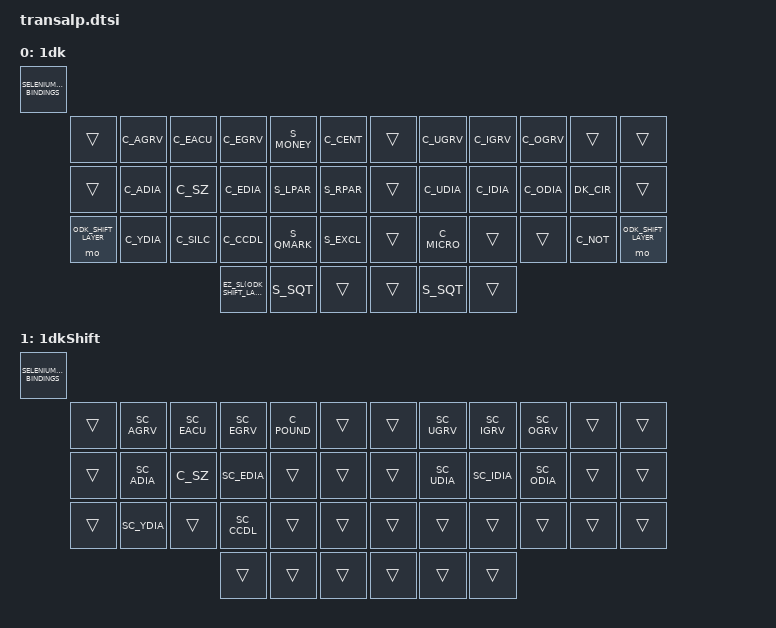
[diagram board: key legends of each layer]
#ifndef USE_ALPHA_ON_OUTER_KEYS

/**
 * This adds a dead key (1dk) to access all common German/French/Italian chars.
 * (Note that QWERTZ-ch natively supports these three languages.)
 *
 * Recommended layouts:
 *  - QWERTZ-ch, used in Switzerland, Luxembourg and Lichtenstein
 *  - QWERTZ-de, used in Germany and Austria
 *  - QWERTY-it, used in Italy (TODO)
 *
 * Language-specific chars:
 *  - German: äöü (diaeresis), ß
 *  - French: é (acute), èàù (grave), ç (cedilla), âêîôû (circumflex), ëïüÿ (diaeresis), œ, æ
 *  - Italian: é (acute), àèìòù (grave)
 *
 * Unsupported chars: (not supported by QWERTZ-de/AZERTY-fr/QWERTY-it, resp.)
 *  - German: uppercase ß
 *  - French: œ, æ
 *  - Italian: ő, circumflex (rare / deprecated)
 *  - advanced punctuation signs: „“, «», …, –—
 *
 * Some of this unsupported chars would be nice to have, and could be added
 * with CP1252 or other OS-specific input methods.
**/

#define ODK_LAYER        EXTRA_LAYERS_START_INDEX
#define ODK_SHIFT_LAYER (EXTRA_LAYERS_START_INDEX + 1)

#define  K_ODKS    &mo ODK_SHIFT_LAYER  // Shift key in the 1dk layer
#define SK_ODKS &EZ_SL(ODK_SHIFT_LAYER) // Shift key in the 1dk layer (sticky)

// Override the standard base layer, to replace SEMI with a positional dead key (1dk).
// The 3×10 grid contains no symbols, only key references.

&base_layer {
  bindings = <SELENIUM_KEYMAP_BINDINGS(
    &kp LTOP    ,  &kp Q &kp W &kp E &kp R &kp T  ,  &kp Y  &kp U  &kp I     &kp O   &kp P             ,  &kp RTOP   ,
    &kp LHOME   ,  &H4 A &H3 S &H2 D &H1 F &kp G  ,  &kp H  &H1 J  &H2 K     &H3 L   &EZ_SL(ODK_LAYER) ,  &kp RHOME  ,
    &kp LSHIFT  ,  &kp Z &kp X &kp C &kp V &kp B  ,  &kp N  &kp M  &kp COMMA &kp DOT &kp FSLH          ,  &kp RSHIFT ,
        LTHUMB_TUCK , LTHUMB_HOME , LTHUMB_REACH  ,  RTHUMB_REACH , RTHUMB_HOME , RTHUMB_TUCK
  )>;
};

// Extra layers defined specifically for this keymap.
// The 3×10 grid contains only symbols, no key references.

/ {
  keymap {
    compatible = "zmk,keymap";

    //  |---------------|---------------|
    //  |    à é è € ¢  |  · ù ì ò ·    |
    //  |    ä ß ë ( )  |  · ü ï ö ^    |
    //  |    ÿ § ç ? !  |  · µ · · ¬    |
    //  |---------------|---------------|

    one_dead_key {
      display-name = "1dk";
      bindings = <SELENIUM_KEYMAP_BINDINGS(
        &trans  ,  C_AGRV  C_EACU  C_EGRV  S_MONEY C_CENT   ,   &trans  C_UGRV  C_IGRV  C_OGRV  &trans  ,  &trans ,
        &trans  ,  C_ADIA  C_SZ    C_EDIA  S_LPAR  S_RPAR   ,   &trans  C_UDIA  C_IDIA  C_ODIA  DK_CIR  ,  &trans ,
        K_ODKS  ,  C_YDIA  C_SILC  C_CCDL  S_QMARK S_EXCL   ,   &trans  C_MICRO &trans  &trans  C_NOT   ,  K_ODKS ,
                                 SK_ODKS , S_SQT , &trans   ,   &trans , S_SQT , &trans
      )>;
    };

    //  |---------------|---------------|
    //  |    À É È £ ·  |  · Ù Ì Ò ·    |
    //  |    Ä ẞ Ë · ·  |  · Ü Ï Ö ·    |
    //  |    Ÿ · Ç · ·  |  · · · · ·    |
    //  |---------------|---------------|

    one_dead_key_shift {
      display-name = "1dkShift";
      bindings = <SELENIUM_KEYMAP_BINDINGS(
        &trans  ,  SC_AGRV SC_EACU SC_EGRV C_POUND &trans   ,   &trans  SC_UGRV SC_IGRV SC_OGRV &trans  ,  &trans ,
        &trans  ,  SC_ADIA C_SZ    SC_EDIA &trans  &trans   ,   &trans  SC_UDIA SC_IDIA SC_ODIA &trans  ,  &trans ,
        &trans  ,  SC_YDIA &trans  SC_CCDL &trans  &trans   ,   &trans  &trans  &trans  &trans  &trans  ,  &trans ,
                                 &trans , &trans , &trans   ,   &trans , &trans , &trans
      )>;
    };

  };
};

#endif // USE_ALPHA_ON_OUTER_KEYS
